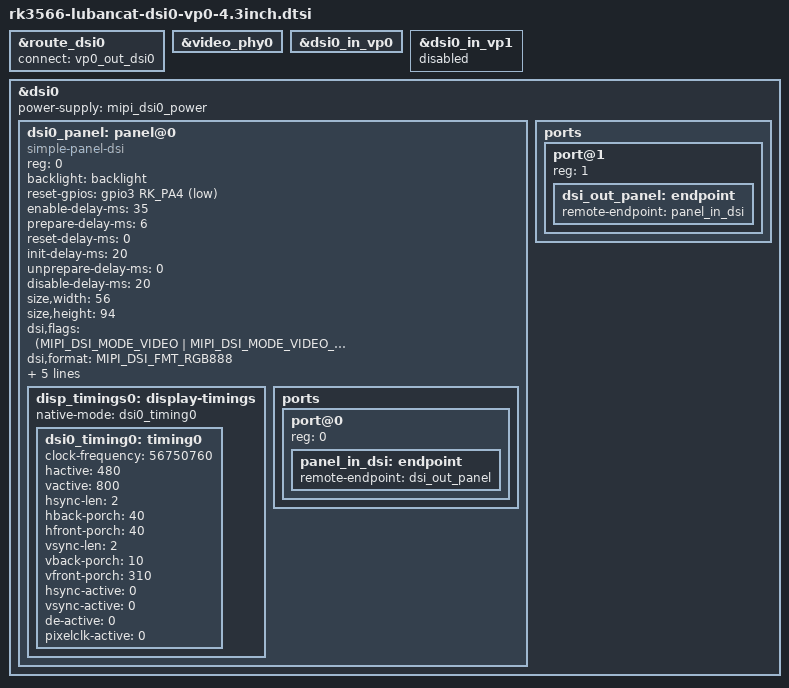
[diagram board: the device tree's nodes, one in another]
// SPDX-License-Identifier: (GPL-2.0+ OR MIT)
&route_dsi0 {
	status = "okay";
	connect = <&vp0_out_dsi0>;
};

&video_phy0 {
	status = "okay";
};

&dsi0_in_vp0 {
	status = "okay";
};

&dsi0_in_vp1 {
	status = "disabled";
};

&dsi0 {
	status = "okay";
	power-supply = <&mipi_dsi0_power>;

	dsi0_panel: panel@0 {
		compatible = "simple-panel-dsi";
		reg = <0>;
		backlight = <&backlight>;
		reset-gpios = <&gpio3 RK_PA4 GPIO_ACTIVE_LOW>;

		enable-delay-ms = <35>;
		prepare-delay-ms = <6>;
		reset-delay-ms = <0>;
		init-delay-ms = <20>;
		unprepare-delay-ms = <0>;
		disable-delay-ms = <20>;

		size,width = <56>;
		size,height = <94>;

		dsi,flags = <(MIPI_DSI_MODE_VIDEO | MIPI_DSI_MODE_VIDEO_BURST | MIPI_DSI_MODE_LPM)>;
		dsi,format = <MIPI_DSI_FMT_RGB888>;
		dsi,lanes  = <2>;

		panel-init-sequence = [
			39 00 04 99 71 02 a2
			39 00 04 99 71 02 a3
			39 00 04 99 71 02 a4
			39 00 08 b0 22 57 1e 61 2f 57 61
			39 00 03 b7 64 64
			39 00 03 bf b4 b4
			39 00 26 c8 00 00 13 24 44 00 74 03 b8 04 11 16 08 86 04 21 d3 02 10 0f 22 4d 0e 90 09 32 f0 0b 40 0e f3 7d 0e a9 bf 03 c4
			39 00 26 c9 00 00 13 24 44 00 74 03 b8 04 11 16 08 86 04 21 d3 02 10 0f 22 4d 0e 90 09 32 f0 0b 40 0e f3 7d 0e a9 bf 03 c4
			39 00 07 d7 10 0c 36 19 90 90
			39 00 21 a3 51 03 80 cf 44 00 00 00 00 04 78 78 00 1a 00 45 05 00 00 00 00 46 00 00 02 20 52 00 05 00 00 ff
			39 00 2d a6 02 00 24 55 35 00 38 00 78 78 00 24 55 36 00 37 00 78 78 02 ac 51 3a 00 00 00 78 78 03 ac 21 00 04 00 00 78 78 3e 00 06 00 00 00 00
			39 00 31 a7 19 19 00 64 40 07 16 40 00 04 03 78 78 00 64 40 25 34 00 00 02 01 78 78 00 64 40 4b 5a 00 00 02 01 78 78 00 24 40 69 78 00 00 00 00 78 78 00 44
			39 00 26 ac 08 0a 11 00 13 03 1b 18 06 1a 19 1b 1b 1b 18 1b 09 0b 10 02 12 01 1b 18 06 1a 19 1b 1b 1b 18 1b ff 67 ff 67 00
			39 00 08 ad cc 40 46 11 04 78 78
			39 00 0f e8 30 07 00 94 94 9c 00 e2 04 00 00 00 00 ef
			39 00 22 e7 8b 3c 00 0c f0 5d 00 5d 00 5d 00 5d 00 ff 00 08 7b 00 00 c8 6a 5a 08 1a 3c 00 81 01 cc 01 7f f0 22
			05 78 01 11
			05 14 01 29
		];

		panel-exit-sequence = [
			05 78 01 28
			05 00 01 10
		];

		disp_timings0: display-timings {
			native-mode = <&dsi0_timing0>;
			dsi0_timing0: timing0 {
				clock-frequency = <56750760>;
				hactive = <480>;
				vactive = <800>;
				hsync-len = <2>;
				hback-porch = <40>;
				hfront-porch = <40>;
				vsync-len = <2>;
				vback-porch = <10>;
				vfront-porch = <310>;
				hsync-active = <0>;
				vsync-active = <0>;
				de-active = <0>;
				pixelclk-active = <0>;
			};
		};

		ports {
			#address-cells = <1>;
			#size-cells = <0>;
			port@0 {
				reg = <0>;
				panel_in_dsi: endpoint {
					remote-endpoint = <&dsi_out_panel>;
				};
			};
		};
	};

	ports {
		#address-cells = <1>;
		#size-cells = <0>;

		port@1 {
			reg = <1>;
			dsi_out_panel: endpoint {
				remote-endpoint = <&panel_in_dsi>;
			};
		};
	};
};
